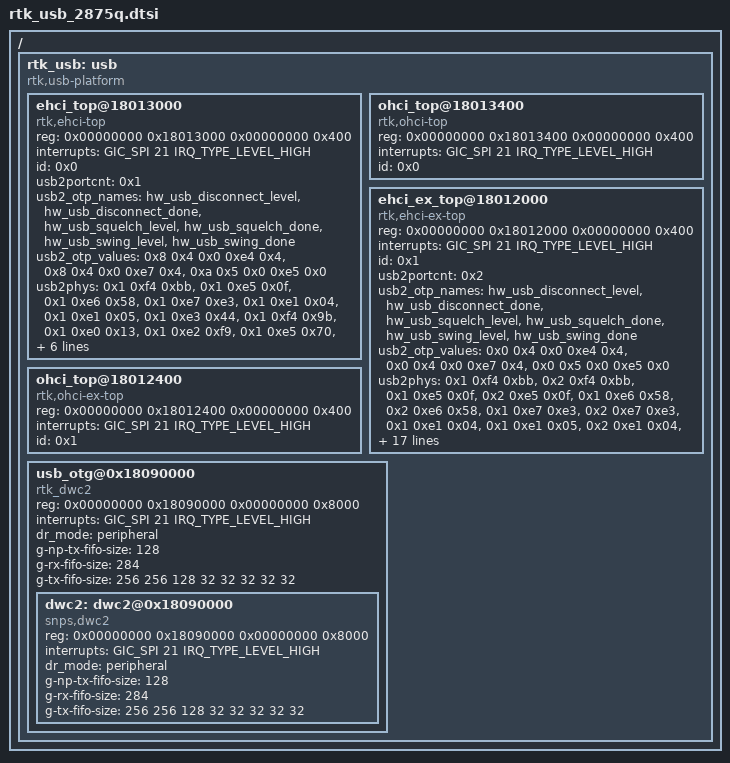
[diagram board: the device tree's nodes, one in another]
/*
 * RTK TV usb host driver device tree in the 64 bits version;
 * including the base address, parameters of phy etc.
 *
 */

/ {
	#address-cells = <1>;
	#size-cells = <1>;
	rtk_usb: usb {
		compatible = "rtk,usb-platform";
		#address-cells = <2>;
		#size-cells = <2>;
	       ranges;

		ehci_top@18013000 {
			compatible = "rtk,ehci-top";
			reg = <0x00000000 0x18013000 0x00000000 0x400>;
            		interrupts = <GIC_SPI 21 IRQ_TYPE_LEVEL_HIGH>;
            		id = <0x0>;
            		usb2portcnt = <0x1>;
            		usb2_otp_names = "hw_usb_disconnect_level", "hw_usb_disconnect_done",
			                             "hw_usb_squelch_level", "hw_usb_squelch_done",
			                             "hw_usb_swing_level", "hw_usb_swing_done";
			                             
			usb2_otp_values = <0x8 0x4 0x0 0xe4 0x4>,/* otp_offset/bitsnum/page/reg/bits_offset */
							<0x8 0x4 0x0 0xe7 0x4>,
							<0xa 0x5 0x0 0xe5 0x0>;
			usb2phys = <0x1  0xf4  0xbb>, 
					    <0x1  0xe5  0x0f>, 
					    <0x1  0xe6  0x58>, 
					    <0x1  0xe7  0xe3>, 
					    <0x1  0xe1  0x04>,  
					    <0x1  0xe1  0x05>,  
					    <0x1  0xe3  0x44>, 
					    <0x1  0xf4  0x9b>, 
					    <0x1  0xe0  0x13>,
					    <0x1  0xe2  0xf9>, 
					    <0x1  0xe5  0x70>, 
					    <0x1  0xf4  0xbb>, 
					    <0x1  0xe3  0x03>, 
					    <0x1  0xe4  0x55>, 	
					    <0x1  0xf4  0x9b>, 
					    <0x1  0xe4  0x6a>, 
					    <0x1  0xe7  0x61>, 
					    <0x1  0xf4  0xbb>, 
					    <0x1  0xe0  0x22>, 
					    <0x1  0xe0  0x26>, 
					    <0x1  0xf4  0x9b>, 
					    <0x1  0xe2  0x7a>, 
					    <0x1  0xe7  0x81>, 
					    <0x1  0xe6  0x02>, 
					    <0x1  0xf5  0x95>, 
					    <0x1  0xf7  0xba>, 
					    <0x1  0xf4  0xdb>,    
					    <0x1  0xe1  0xfb>,
					    <0x1  0xf4  0x9b>;
		};

		ohci_top@18013400 {
			compatible = "rtk,ohci-top";
			reg = <0x00000000 0x18013400 0x00000000 0x400>;
			interrupts = <GIC_SPI 21 IRQ_TYPE_LEVEL_HIGH>;
			id = <0x0>;
		};

		ehci_ex_top@18012000 {
			compatible = "rtk,ehci-ex-top";
			reg = <0x00000000 0x18012000 0x00000000 0x400>;
            		interrupts = <GIC_SPI 21 IRQ_TYPE_LEVEL_HIGH>;
            		id = <0x1>;
            		usb2portcnt = <0x2>;
            		usb2_otp_names = "hw_usb_disconnect_level", "hw_usb_disconnect_done",
			                             "hw_usb_squelch_level", "hw_usb_squelch_done",
			                             "hw_usb_swing_level", "hw_usb_swing_done";
			                             
			usb2_otp_values = <0x0 0x4 0x0 0xe4 0x4>,/* otp_offset/bitsnum/page/reg/bits_offset */
							<0x0 0x4 0x0 0xe7 0x4>,
							<0x0 0x5 0x0 0xe5 0x0>;
			usb2phys = <0x1  0xf4  0xbb>, 
					    <0x2  0xf4  0xbb>, 
					    <0x1  0xe5  0x0f>, 
					    <0x2  0xe5  0x0f>,  
					    <0x1  0xe6  0x58>, 
					    <0x2  0xe6  0x58>, 
					    <0x1  0xe7  0xe3>, 
					    <0x2  0xe7  0xe3>, 
					    <0x1  0xe1  0x04>,  
					    <0x1  0xe1  0x05>,   
					    <0x2  0xe1  0x04>,  
					    <0x2  0xe1  0x05>,    
					    <0x1  0xf4  0x9b>, 
					    <0x2  0xf4  0x9b>, 
					    <0x1  0xe0  0x13>, 
					    <0x2  0xe0  0x13>, 
					    <0x1  0xe2  0xf9>, 
					    <0x2  0xe2  0xf9>, 
					    <0x1  0xe5  0x79>, 
					    <0x2  0xe5  0x79>, 	
					    <0x1  0xf4  0xbb>, 
					    <0x2  0xf4  0xbb>, 
					    <0x1  0xe3  0x03>, 
					    <0x2  0xe3  0x03>, 
					    <0x1  0xf4  0xdb>, 
					    <0x2  0xf4  0xdb>,
					    <0x1  0xe7  0x55>, 
					    <0x2  0xe7  0x55>, 	
					    <0x1  0xf4  0x9b>, 
					    <0x2  0xf4  0x9b>, 
					    <0x1  0xe4  0x6a>, 
					    <0x2  0xe4  0x6a>, 
					    <0x1  0xe7  0x61>, 
					    <0x2  0xe7  0x61>, 
					    <0x1  0xf4  0xbb>, 
					    <0x2  0xf4  0xbb>, 
					    <0x1  0xe0  0x22>, 
					    <0x1  0xe0  0x26>, 
					    <0x2  0xe0  0x22>, 
					    <0x2  0xe0  0x26>, 
					    <0x1  0xf4  0x9b>, 
					    <0x2  0xf4  0x9b>, 
					    <0x1  0xe2  0x7a>, 
					    <0x2  0xe2  0x7a>, 
					    <0x1  0xe7  0x81>, 
					    <0x2  0xe7  0x81>, 
					    <0x1  0xe6  0x02>, 
					    <0x2  0xe6  0x02>, 					    
					    <0x1  0xf5  0x95>, 
					    <0x2  0xf5  0x95>, 
					    <0x1  0xf7  0xba>, 
					    <0x2  0xf7  0xba>, 
					    <0x1  0xf4  0xdb>,
					    <0x2  0xf4  0xdb>,
					    <0x1  0xe1  0xfb>, 
					    <0x2  0xe1  0xfb>,
					    <0x1  0xf4  0x9b>, 
					    <0x2  0xf4  0x9b>,
					    <0x2  0xf3  0x31>,
					    <0x2  0xf4  0x9b>;
		};

		ohci_top@18012400 {
			compatible = "rtk,ohci-ex-top";
			reg = <0x00000000 0x18012400 0x00000000 0x400>;
			interrupts = <GIC_SPI 21 IRQ_TYPE_LEVEL_HIGH>;
			id = <0x1>;
		};		

		usb_otg@0x18090000 {
			compatible = "rtk_dwc2";
			reg = <0x00000000 0x18090000 0x00000000 0x8000>;
			interrupts = <GIC_SPI 21 IRQ_TYPE_LEVEL_HIGH>;
			dr_mode ="peripheral";
			g-np-tx-fifo-size = <128>;
			g-rx-fifo-size = <284>;
			g-tx-fifo-size = <256 256 128 32 32 32 32 32>;			
			/**for dwc2 otg**/
			#address-cells = <2>;
			#size-cells = <2>;
			ranges;
			dwc2: dwc2@0x18090000 {
				compatible = "snps,dwc2";
				reg = <0x00000000 0x18090000 0x00000000 0x8000>;
				interrupts = <GIC_SPI 21 IRQ_TYPE_LEVEL_HIGH>;
				dr_mode ="peripheral";
				g-np-tx-fifo-size = <128>;
				g-rx-fifo-size = <284>;
				g-tx-fifo-size = <256 256 128 32 32 32 32 32>;
			};
		};
	};

  };
